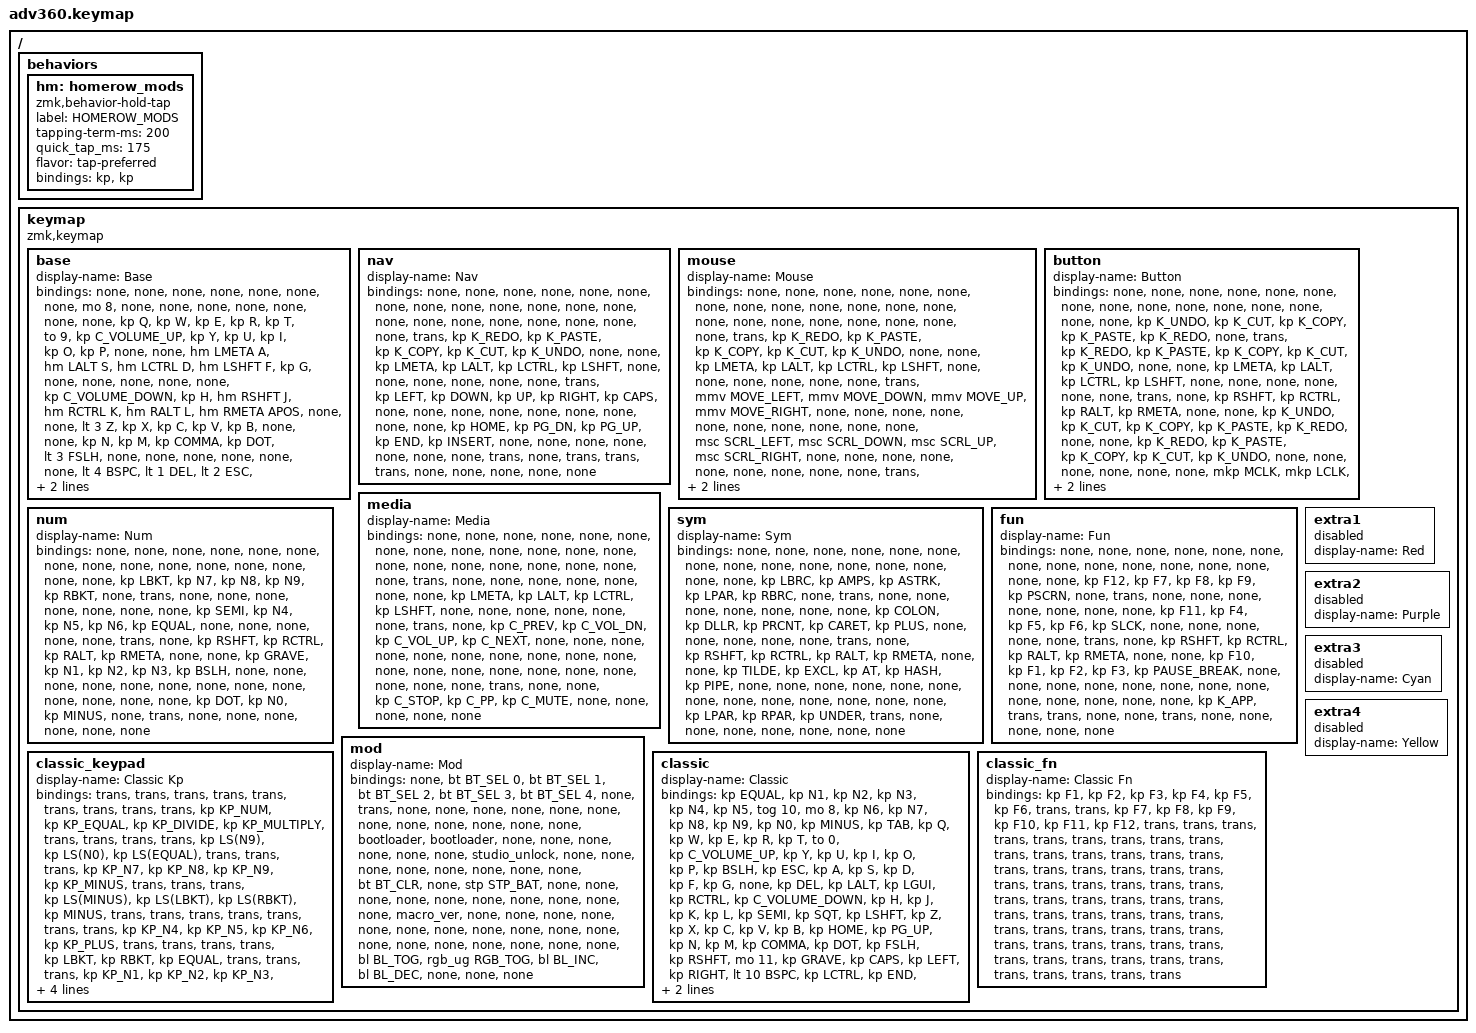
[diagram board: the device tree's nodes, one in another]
#include <behaviors.dtsi>
#include <dt-bindings/zmk/keys.h>
#include <dt-bindings/zmk/bt.h>
#include <dt-bindings/zmk/rgb.h>
#include <dt-bindings/zmk/stp.h>
#include <dt-bindings/zmk/backlight.h>
#include <dt-bindings/zmk/pointing.h>

/ {
    behaviors {
      #include "macros.dtsi"
      #include "version.dtsi"

      hm: homerow_mods {
          compatible = "zmk,behavior-hold-tap";
          label = "HOMEROW_MODS";
          #binding-cells = <2>;
          tapping-term-ms = <200>;
          quick_tap_ms = <175>;
          flavor = "tap-preferred";
          bindings = <&kp>, <&kp>;
      };
    };

  keymap {
    compatible = "zmk,keymap";

    base {
      display-name = "Base";
      bindings = <
        &none &none       &none      &none       &none       &none  &none                                                                 &mo 8             &none  &none       &none       &none      &none          &none
        &none &kp Q       &kp W      &kp E       &kp R       &kp T  &to 9                                                                 &kp C_VOLUME_UP   &kp Y  &kp U       &kp I       &kp O      &kp P          &none
        &none &hm LMETA A &hm LALT S &hm LCTRL D &hm LSHFT F &kp G  &none                    &none   &none      &none       &none         &kp C_VOLUME_DOWN &kp H  &hm RSHFT J &hm RCTRL K &hm RALT L &hm RMETA APOS &none
        &none &lt 3 Z     &kp X      &kp C       &kp V       &kp B                                   &none      &none                                       &kp N  &kp M       &kp COMMA   &kp DOT    &lt 3 FSLH     &none
        &none &none       &none      &none       &none                      &lt 4 BSPC &lt 1 DEL     &lt 2 ESC  &lt 6 TAB   &lt 5 ENTER &lt 7 SPACE                &none       &none       &none      &none          &none
      >;
    };

    // Layer 1
    nav {
      display-name = "Nav";
      bindings = <
        &none  &none      &none     &none      &none      &none  &none                                               &none  &none      &none       &none      &none     &none       &none
        &none  &none      &none     &none      &none      &none  &none                                               &trans &kp K_REDO &kp K_PASTE &kp K_COPY &kp K_CUT &kp K_UNDO  &none
        &none  &kp LMETA  &kp LALT  &kp LCTRL  &kp LSHFT  &none  &none         &none   &none  &none  &none           &trans &kp LEFT   &kp DOWN    &kp UP     &kp RIGHT &kp CAPS    &none
        &none  &none      &none     &none      &none      &none                        &none  &none                         &kp HOME   &kp PG_DN   &kp PG_UP  &kp END   &kp INSERT  &none
        &none  &none      &none     &none      &none                    &none  &trans  &none  &trans &trans  &trans                    &none       &none      &none     &none       &none
      >;
    };

    // Layer 2
    mouse {
      display-name = "Mouse";
      bindings = <
        &none  &none      &none     &none      &none      &none  &none                                              &none  &none            &none           &none          &none             &none       &none
        &none  &none      &none     &none      &none      &none  &none                                              &trans &kp K_REDO       &kp K_PASTE     &kp K_COPY     &kp K_CUT         &kp K_UNDO  &none
        &none  &kp LMETA  &kp LALT  &kp LCTRL  &kp LSHFT  &none  &none         &none  &none  &none  &none           &trans &mmv MOVE_LEFT   &mmv MOVE_DOWN  &mmv MOVE_UP   &mmv MOVE_RIGHT   &none       &none
        &none  &none      &none     &none      &none      &none                       &none  &none                         &msc SCRL_LEFT   &msc SCRL_DOWN  &msc SCRL_UP   &msc SCRL_RIGHT   &none       &none
        &none  &none      &none     &none      &none                    &none  &none  &trans &mkp RCLK &mkp LCLK &mkp MCLK                  &none           &none          &none             &none       &none
      >;
    };

    // Layer 3
    button {
      display-name = "Button";
      bindings = <
        &none  &none      &none     &none      &none       &none       &none                                                       &none  &none       &none       &none      &none     &none       &none
        &none  &kp K_UNDO &kp K_CUT &kp K_COPY &kp K_PASTE &kp K_REDO  &none                                                       &trans &kp K_REDO  &kp K_PASTE &kp K_COPY &kp K_CUT &kp K_UNDO  &none
        &none  &kp LMETA  &kp LALT  &kp LCTRL  &kp LSHFT   &none       &none            &none     &none     &none  &none           &trans &none       &kp RSHFT   &kp RCTRL  &kp RALT  &kp RMETA   &none
        &none  &kp K_UNDO &kp K_CUT &kp K_COPY &kp K_PASTE &kp K_REDO                             &none     &none                         &kp K_REDO  &kp K_PASTE &kp K_COPY &kp K_CUT &kp K_UNDO  &none
        &none  &none      &none     &none      &none                          &mkp MCLK &mkp LCLK &mkp RCLK &mkp RCLK &mkp LCLK &mkp MCLK             &none       &none      &none     &none       &none
      >;
    };

    // Layer 4
    media {
      display-name = "Media";
      bindings = <
        &none  &none      &none     &none      &none      &none  &none                                              &none  &none &none      &none        &none        &none       &none
        &none  &none      &none     &none      &none      &none  &none                                              &trans &none &none      &none        &none        &none       &none
        &none  &kp LMETA  &kp LALT  &kp LCTRL  &kp LSHFT  &none  &none         &none  &none  &none  &none           &trans &none &kp C_PREV &kp C_VOL_DN &kp C_VOL_UP &kp C_NEXT  &none
        &none  &none      &none     &none      &none      &none                       &none  &none                         &none &none      &none        &none        &none       &none
        &none  &none      &none     &none      &none                    &trans &none  &none  &kp C_STOP &kp C_PP &kp C_MUTE      &none      &none        &none        &none       &none
      >;
    };

    // Layer 5
    num {
      display-name = "Num";
      bindings = <
        &none  &none      &none   &none   &none   &none      &none                                              &none  &none &none     &none     &none    &none      &none
        &none  &kp LBKT   &kp N7  &kp N8  &kp N9  &kp RBKT   &none                                              &trans &none &none     &none     &none    &none      &none
        &none  &kp SEMI   &kp N4  &kp N5  &kp N6  &kp EQUAL  &none         &none  &none     &none &none         &trans &none &kp RSHFT &kp RCTRL &kp RALT &kp RMETA  &none
        &none  &kp GRAVE  &kp N1  &kp N2  &kp N3  &kp BSLH                        &none     &none                      &none &none     &none     &none    &none      &none
        &none  &none      &none   &none   &none                    &kp DOT &kp N0 &kp MINUS &none &trans &none               &none     &none     &none    &none      &none
      >;
    };

    // Layer 6
    sym {
      display-name = "Sym";
      bindings = <
        &none  &none      &none     &none      &none      &none     &none                                            &none  &none &none     &none     &none    &none      &none
        &none  &kp LBRC   &kp AMPS  &kp ASTRK  &kp LPAR   &kp RBRC  &none                                            &trans &none &none     &none     &none    &none      &none
        &none  &kp COLON  &kp DLLR  &kp PRCNT  &kp CARET  &kp PLUS  &none         &none  &none      &none  &none     &trans &none &kp RSHFT &kp RCTRL &kp RALT &kp RMETA  &none
        &none  &kp TILDE  &kp EXCL  &kp AT     &kp HASH   &kp PIPE                       &none      &none                   &none &none     &none     &none    &none      &none
        &none  &none      &none     &none      &none                    &kp LPAR &kp RPAR &kp UNDER &trans &none &none            &none     &none     &none    &none      &none
      >;
    };

    // Layer 7
    fun {
      display-name = "Fun";
      bindings = <
        &none  &none      &none   &none   &none   &none      &none                                              &none  &none &none     &none     &none    &none      &none
        &none  &kp F12    &kp F7  &kp F8  &kp F9  &kp PSCRN  &none                                              &trans &none &none     &none     &none    &none      &none
        &none  &kp F11    &kp F4  &kp F5  &kp F6  &kp SLCK   &none         &none  &none     &none &none         &trans &none &kp RSHFT &kp RCTRL &kp RALT &kp RMETA  &none
        &none  &kp F10    &kp F1  &kp F2  &kp F3  &kp PAUSE_BREAK                 &none     &none                      &none &none     &none     &none    &none      &none
        &none  &none      &none   &none   &none                  &kp K_APP &trans &trans    &none &none &trans               &none     &none     &none    &none      &none
      >;
    };

    // Layer 8
    mod {
      display-name = "Mod";
      bindings = <
        &none &bt BT_SEL 0 &bt BT_SEL 1 &bt BT_SEL 2 &bt BT_SEL 3 &bt BT_SEL 4 &none                                                                     &trans                 &none        &none        &none        &none &none &none
        &none &none        &none        &none        &none        &none        &bootloader                                                               &bootloader            &none        &none        &none        &none &none &none
        &studio_unlock &none        &none        &none        &none        &none        &none                   &none &none &bt BT_CLR &none                      &stp STP_BAT &none        &none        &none        &none &none &none
        &none &none        &none        &none        &macro_ver   &none                                      &none &none                                                        &none        &none        &none        &none &none &none
        &none &none        &none        &none        &none                                       &none &none &none &none      &bl BL_TOG &rgb_ug RGB_TOG                                     &bl BL_INC   &bl BL_DEC   &none &none &none
      >;
    };

    // Layer 9
    classic {
      display-name = "Classic";
      bindings = <
        &kp EQUAL &kp N1    &kp N2   &kp N3   &kp N4     &kp N5 &tog 10                                                          &mo 8             &kp N6 &kp N7    &kp N8    &kp N9   &kp N0   &kp MINUS
        &kp TAB   &kp Q     &kp W    &kp E    &kp R      &kp T  &to 0                                                            &kp C_VOLUME_UP   &kp Y  &kp U     &kp I     &kp O    &kp P    &kp BSLH
        &kp ESC   &kp A     &kp S    &kp D    &kp F      &kp G  &none                 &kp DEL &kp LALT &kp LGUI  &kp RCTRL       &kp C_VOLUME_DOWN &kp H  &kp J     &kp K     &kp L    &kp SEMI &kp SQT
        &kp LSHFT &kp Z     &kp X    &kp C    &kp V      &kp B                                &kp HOME &kp PG_UP                                   &kp N  &kp M     &kp COMMA &kp DOT  &kp FSLH &kp RSHFT
        &mo 11    &kp GRAVE &kp CAPS &kp LEFT &kp RIGHT                &lt 10 BSPC &kp LCTRL  &kp END  &kp PG_DN &kp ENTER &kp SPACE               &kp UP &kp DOWN  &kp LBKT  &kp RBKT &mo 11

      >;
    };

    // Layer 10
    classic_keypad {
      display-name = "Classic Kp";
      bindings = <
        &trans &trans &trans        &trans       &trans       &trans        &trans                                               &trans &trans &kp KP_NUM &kp KP_EQUAL &kp KP_DIVIDE &kp KP_MULTIPLY &trans
        &trans &trans &trans        &kp LS(N9)   &kp LS(N0)   &kp LS(EQUAL) &trans                                               &trans &trans &kp KP_N7  &kp KP_N8    &kp KP_N9     &kp KP_MINUS    &trans
        &trans &trans &kp LS(MINUS) &kp LS(LBKT) &kp LS(RBKT) &kp MINUS     &trans         &trans &trans &trans &trans           &trans &trans &kp KP_N4  &kp KP_N5    &kp KP_N6     &kp KP_PLUS     &trans
        &trans &trans &trans        &kp LBKT     &kp RBKT     &kp EQUAL                           &trans &trans                         &trans &kp KP_N1  &kp KP_N2    &kp KP_N3     &kp KP_ENTER    &trans
        &trans &trans &trans        &trans       &trans                             &trans &trans &trans &trans &trans &kp KP_N0               &trans     &trans       &kp KP_DOT    &trans          &trans
      >;
    };

    // Layer 11
    classic_fn {
      display-name = "Classic Fn";
      bindings = <
        &kp F1 &kp F2 &kp F3 &kp F4 &kp F5 &kp F6 &trans                                           &trans &kp F7 &kp F8 &kp F9 &kp F10 &kp F11 &kp F12
        &trans &trans &trans &trans &trans &trans &trans                                           &trans &trans &trans &trans &trans  &trans  &trans
        &trans &trans &trans &trans &trans &trans &trans        &trans &trans &trans &trans        &trans &trans &trans &trans &trans  &trans  &trans
        &trans &trans &trans &trans &trans &trans                      &trans &trans                      &trans &trans &trans &trans  &trans  &trans
        &trans &trans &trans &trans &trans               &trans &trans &trans &trans &trans &trans               &trans &trans &trans  &trans  &trans
      >;
    };

    extra1 { 
      display-name = "Red";    
      status = "reserved";
    };

    extra2 { 
      display-name = "Purple";    
      status = "reserved";
    };

    extra3 { 
      display-name = "Cyan";    
      status = "reserved";
    };

    extra4 { 
      display-name = "Yellow";    
      status = "reserved";
    };
  };
};
